# PRU_ICSSG0_PR1_TASKS_MGR_PRU0_PR1_TASKS_MGR_PRU0_MMR_local register map
Vendor: Texas Instruments
Peripheral module from a debugger description file (folder am65x).
Registers are 32-bit, read-write, reset 0x0 unless marked. A register's access mark holds for its fields unless they carry their own. Offsets are as the file gives them; lines under a group give offsets from that group; [hi:lo] are bit positions; {n}, {i} and the like mark numbered series; 'fields as' and 'values as' point back to an identical list; <NAME> marks a mode.

## PRU_ICSSG0_PR1_TASKS_MGR_PRU0_PR1_TASKS_MGR_PRU0_MMR
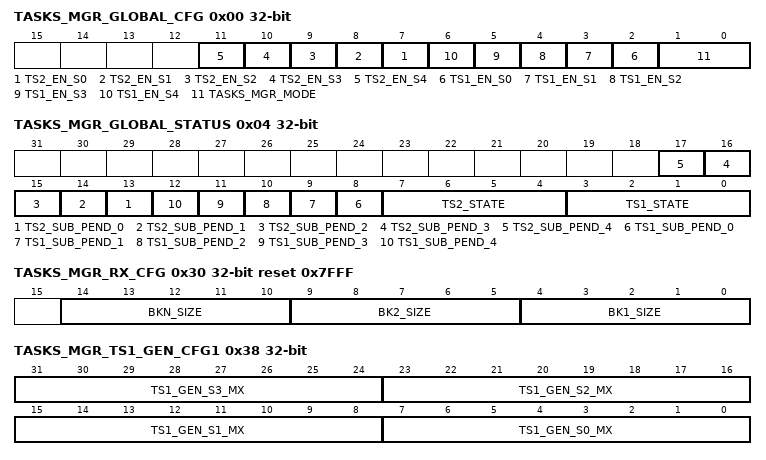
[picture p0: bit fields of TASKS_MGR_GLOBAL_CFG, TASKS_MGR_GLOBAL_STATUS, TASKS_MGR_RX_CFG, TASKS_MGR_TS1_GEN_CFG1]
0x00 TASKS_MGR_GLOBAL_CFG — Global Configuration
  [n+7] TS2_EN_S{n} (n=0..4) — TS2 Sub{n} 0: Disabled 1: Enabled
  [n+2] TS1_EN_S{n} (n=0..4) — TS1 Sub{n} 0: Disabled 1: Enabled
  [1:0] TASKS_MGR_MODE — TaskSwap Mode 0: Disabled 1: RXTX 2: General_HW
0x04 TASKS_MGR_GLOBAL_STATUS ro — Global Status
  [n+13] TS2_SUB_PEND_{n} (n=0..4) — Task2 Sub{n} Pend State
  [n+8] TS1_SUB_PEND_{n} (n=0..4) — Task1 Sub{n} Pend State
  [7:4] TS2_STATE — Task2 State
  [3:0] TS1_STATE — Task1 State
{0x8+4i} TASKS_MGR_TS1_PC_S{i} (i=0..4) — TS1 Sub{i} PC
  [13:0] TS1_PC_S{i}
{0x1C+4i} TASKS_MGR_TS2_PC_S{i} (i=0..4) — TS2 Sub{i} PC
  [13:0] TS2_PC_S{i}
0x30 TASKS_MGR_RX_CFG reset 0x7FFF — RX Configuration
  [14:10] BKN_SIZE — RX BKN Size, After BK1 and BK@, then after another 1 to 32 Bytes
  [9:5] BK2_SIZE — RX BK2 Size, The Second 1 to 32 Bytes trigger
  [4:0] BK1_SIZE — RX BK1 Size , The first 1 to 32 Bytes trigger
0x34 TASKS_MGR_TX_CFG reset 0x1F — TX Configuration
  [5:0] TX_WM — TX L2 Water Mark Level 1 to 64 Bytes
0x38 TASKS_MGR_TS1_GEN_CFG1 — Generic TS1 Configuration1
  [8n+7:8n] TS1_GEN_S{n}_MX (n=0..3) — TS1 Generic Sub{n} MX Select
0x3C TASKS_MGR_TS1_GEN_CFG2 — Generic TS1 Configuration2
  [7:0] TS1_GEN_S4_MX — TS1 Generic Sub4 MX Select
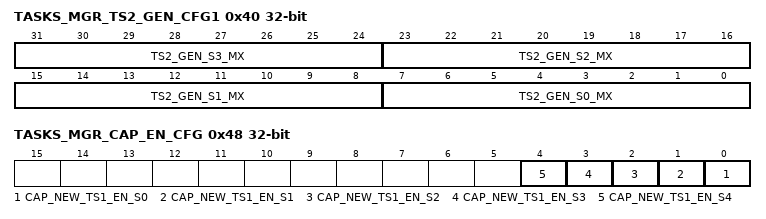
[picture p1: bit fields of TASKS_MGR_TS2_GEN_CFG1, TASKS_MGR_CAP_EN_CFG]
0x40 TASKS_MGR_TS2_GEN_CFG1 — Generic TS2 Configuration1
  [8n+7:8n] TS2_GEN_S{n}_MX (n=0..3) — TS2 Generic Sub{n} MX Select
0x44 TASKS_MGR_TS2_GEN_CFG2 — Generic TS2 Configuration2
  [7:0] TS2_GEN_S4_MX — TS2 Generic Sub4 MX Select
0x48 TASKS_MGR_CAP_EN_CFG — This register allows you to enable a capture of a new event when you are active in the sub task. By default, all new events to the same active task are masked until you exit that sub task from being captured When disabled (reset state). All new events to the current active task are masked from being captured. Only when this task is completed a new event can get captured for that task. When enabled, a new event which occurs in a current active task will get captured, when that task yields it will reenter that same task if not other higher priority events are pending
  [n] CAP_NEW_TS1_EN_S{n} (n=0..4) — Capture new event enable. TS1 Sub{n}.
